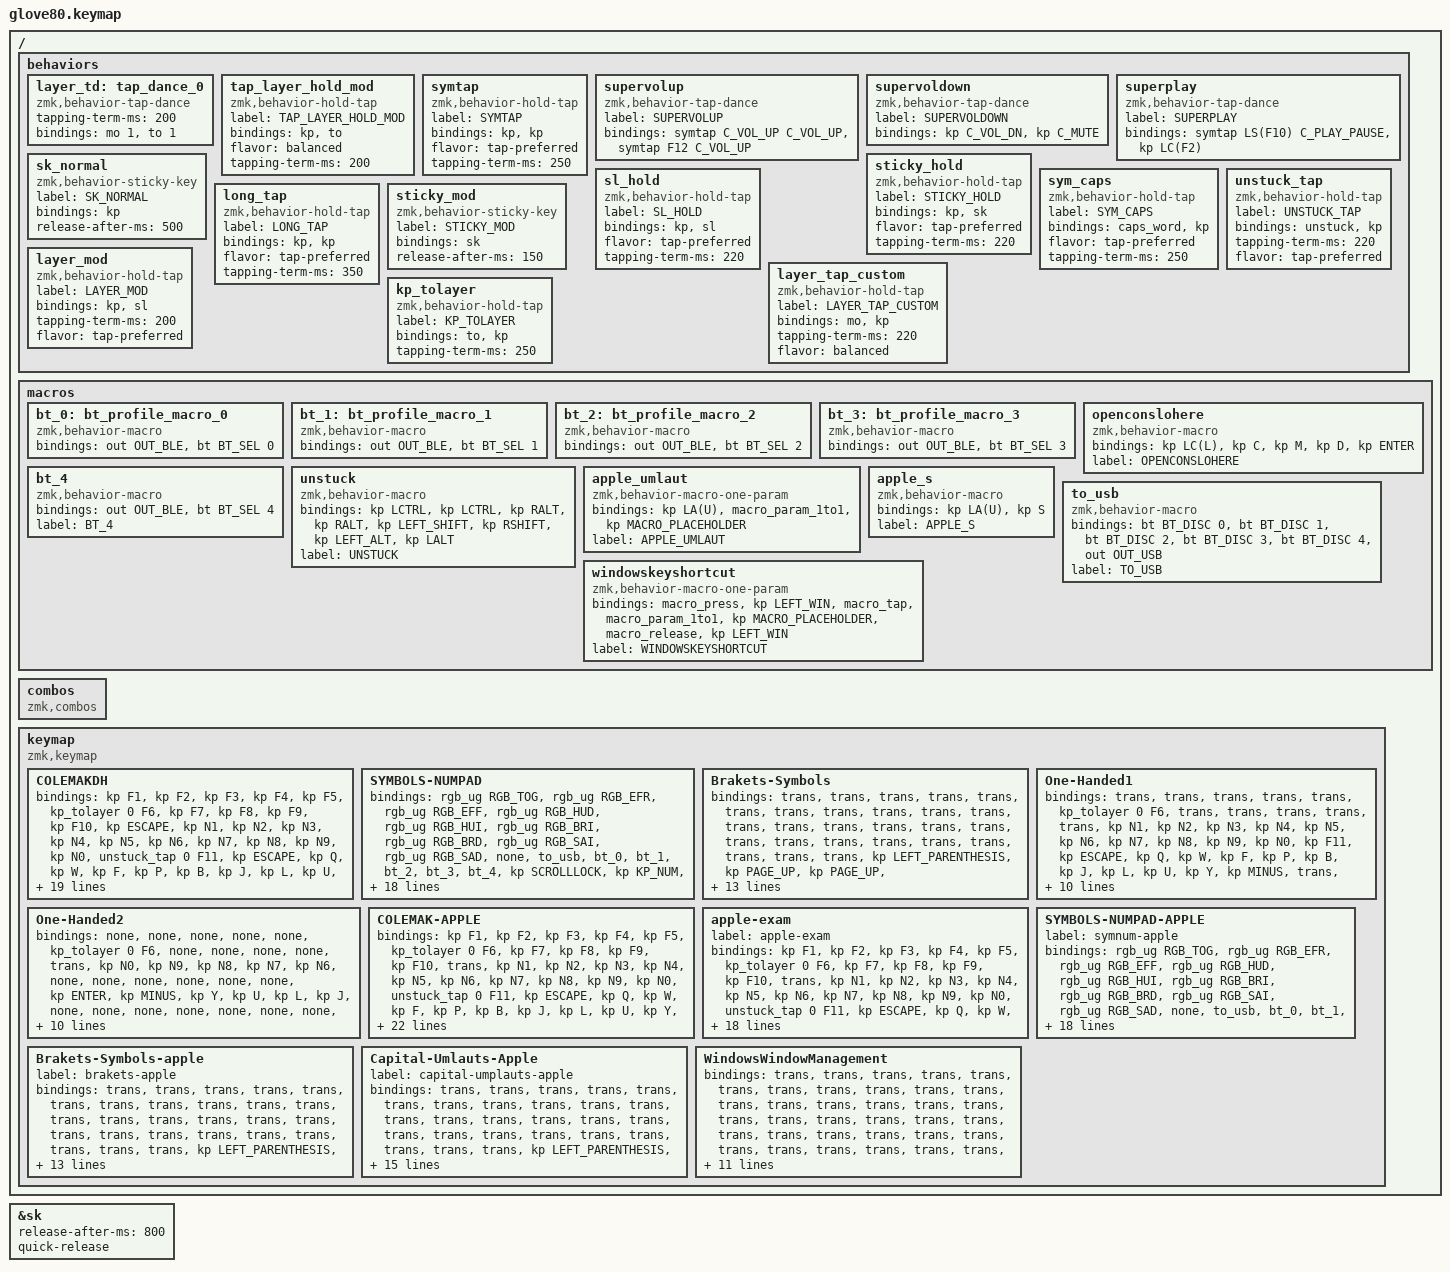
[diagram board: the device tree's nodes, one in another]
/*
 * Copyright (c) 2020 The ZMK Contributors
 *
 * SPDX-License-Identifier: MIT
 */

#include <behaviors.dtsi>
#include <dt-bindings/zmk/backlight.h>
#include <dt-bindings/zmk/bt.h>
#include <dt-bindings/zmk/keys.h>
#include <dt-bindings/zmk/outputs.h>
#include <dt-bindings/zmk/rgb.h>

// layers

#define DEFAULT 0
#define LOWER 1
#define MAGIC 2

&sk {
    release-after-ms = <800>;
    quick-release;
};

/ {
    behaviors {
        // For the "layer" key, it'd nice to be able to use it as either a shift or a toggle.
        // Configure it as a tap dance, so the first tap (or hold) is a &mo and the second tap is a &to

        layer_td: tap_dance_0 {
            compatible = "zmk,behavior-tap-dance";
            #binding-cells = <0>;
            tapping-term-ms = <200>;
            bindings = <&mo 1>, <&to 1>;
        };

        tap_layer_hold_mod: tap_layer_hold_mod {
            compatible = "zmk,behavior-hold-tap";
            label = "TAP_LAYER_HOLD_MOD";
            bindings = <&kp>, <&to>;

            #binding-cells = <2>;
            flavor = "balanced";
            tapping-term-ms = <200>;
        };

        symtap: symtap {
            compatible = "zmk,behavior-hold-tap";
            label = "SYMTAP";
            bindings = <&kp>, <&kp>;

            #binding-cells = <2>;
            flavor = "tap-preferred";
            tapping-term-ms = <250>;
        };

        supervolup: supervolup {
            compatible = "zmk,behavior-tap-dance";
            label = "SUPERVOLUP";
            #binding-cells = <0>;
            bindings = <&symtap C_VOL_UP C_VOL_UP>, <&symtap F12 C_VOL_UP>;
        };

        supervoldown: supervoldown {
            compatible = "zmk,behavior-tap-dance";
            label = "SUPERVOLDOWN";
            #binding-cells = <0>;
            bindings = <&kp C_VOL_DN>, <&kp C_MUTE>;
        };

        superplay: superplay {
            compatible = "zmk,behavior-tap-dance";
            label = "SUPERPLAY";
            #binding-cells = <0>;
            bindings = <&symtap LS(F10) C_PLAY_PAUSE>, <&kp LC(F2)>;
        };

        sk_normal: sk_normal {
            compatible = "zmk,behavior-sticky-key";
            label = "SK_NORMAL";
            bindings = <&kp>;
            #binding-cells = <1>;
            release-after-ms = <500>;
        };

        sticky_hold: sticky_hold {
            compatible = "zmk,behavior-hold-tap";
            label = "STICKY_HOLD";
            bindings = <&kp>, <&sk>;

            #binding-cells = <2>;
            flavor = "tap-preferred";
            tapping-term-ms = <220>;
        };

        sl_hold: sl_hold {
            compatible = "zmk,behavior-hold-tap";
            label = "SL_HOLD";
            bindings = <&kp>, <&sl>;

            #binding-cells = <2>;
            flavor = "tap-preferred";
            tapping-term-ms = <220>;
        };

        sym_caps: sym_caps {
            compatible = "zmk,behavior-hold-tap";
            label = "SYM_CAPS";
            bindings = <&caps_word>, <&kp>;

            #binding-cells = <2>;
            flavor = "tap-preferred";
            tapping-term-ms = <250>;
        };

        unstuck_tap: unstuck_tap {
            compatible = "zmk,behavior-hold-tap";
            label = "UNSTUCK_TAP";
            bindings = <&unstuck>, <&kp>;

            #binding-cells = <2>;
            tapping-term-ms = <220>;
            flavor = "tap-preferred";
        };

        long_tap: long_tap {
            compatible = "zmk,behavior-hold-tap";
            label = "LONG_TAP";
            bindings = <&kp>, <&kp>;

            #binding-cells = <2>;
            flavor = "tap-preferred";
            tapping-term-ms = <350>;
        };

        sticky_mod: sticky_mod {
            compatible = "zmk,behavior-sticky-key";
            label = "STICKY_MOD";
            bindings = <&sk>;
            #binding-cells = <1>;
            release-after-ms = <150>;
        };

        layer_mod: layer_mod {
            compatible = "zmk,behavior-hold-tap";
            label = "LAYER_MOD";
            bindings = <&kp>, <&sl>;

            #binding-cells = <2>;
            tapping-term-ms = <200>;
            flavor = "tap-preferred";
        };

        layer_tap_custom: layer_tap_custom {
            compatible = "zmk,behavior-hold-tap";
            label = "LAYER_TAP_CUSTOM";
            bindings = <&mo>, <&kp>;

            #binding-cells = <2>;
            tapping-term-ms = <220>;
            flavor = "balanced";
        };

        kp_tolayer: kp_tolayer {
            compatible = "zmk,behavior-hold-tap";
            label = "KP_TOLAYER";
            bindings = <&to>, <&kp>;

            #binding-cells = <2>;
            tapping-term-ms = <250>;
        };
    };

    macros {
        bt_0: bt_profile_macro_0 {
            compatible = "zmk,behavior-macro";
            #binding-cells = <0>;
            bindings = <&out OUT_BLE &bt BT_SEL 0>;
        };

        bt_1: bt_profile_macro_1 {
            compatible = "zmk,behavior-macro";
            #binding-cells = <0>;
            bindings = <&out OUT_BLE &bt BT_SEL 1>;
        };

        bt_2: bt_profile_macro_2 {
            compatible = "zmk,behavior-macro";
            #binding-cells = <0>;
            bindings = <&out OUT_BLE &bt BT_SEL 2>;
        };

        bt_3: bt_profile_macro_3 {
            compatible = "zmk,behavior-macro";
            #binding-cells = <0>;
            bindings = <&out OUT_BLE &bt BT_SEL 3>;
        };

        openconslohere: openconslohere {
            compatible = "zmk,behavior-macro";
            #binding-cells = <0>;
            bindings = <&kp LC(L) &kp C &kp M &kp D &kp ENTER>;
            label = "OPENCONSLOHERE";
        };

        bt_4: bt_4 {
            compatible = "zmk,behavior-macro";
            #binding-cells = <0>;
            bindings = <&out OUT_BLE &bt BT_SEL 4>;
            label = "BT_4";
        };

        unstuck: unstuck {
            compatible = "zmk,behavior-macro";
            #binding-cells = <0>;
            bindings = <&kp LCTRL &kp LCTRL &kp RALT &kp RALT &kp LEFT_SHIFT &kp RSHIFT &kp LEFT_ALT &kp LALT>;
            label = "UNSTUCK";
        };

        apple_umlaut: apple_umlaut {
            compatible = "zmk,behavior-macro-one-param";
            #binding-cells = <1>;
            bindings = <&kp LA(U) &macro_param_1to1 &kp MACRO_PLACEHOLDER>;
            label = "APPLE_UMLAUT";
        };

        apple_s: apple_s {
            compatible = "zmk,behavior-macro";
            #binding-cells = <0>;
            bindings = <&kp LA(U) &kp S>;
            label = "APPLE_S";
        };

        to_usb: to_usb {
            compatible = "zmk,behavior-macro";
            #binding-cells = <0>;
            bindings = <&bt BT_DISC 0 &bt BT_DISC 1 &bt BT_DISC 2 &bt BT_DISC 3 &bt BT_DISC 4 &out OUT_USB>;
            label = "TO_USB";
        };

        windowskeyshortcut: windowskeyshortcut {
            compatible = "zmk,behavior-macro-one-param";
            #binding-cells = <1>;
            bindings =
                <&macro_press>,
                <&kp LEFT_WIN>,
                <&macro_tap>,
                <&macro_param_1to1 &kp MACRO_PLACEHOLDER>,
                <&macro_release>,
                <&kp LEFT_WIN>;

            label = "WINDOWSKEYSHORTCUT";
        };
    };

    combos { compatible = "zmk,combos"; };

    keymap {
        compatible = "zmk,keymap";

        COLEMAKDH {
            // ---------------------------------------------------------------------------------------------------------------------------------
            // |  F1   |  F2 |  F3 |  F4  |  F5  |                                                               |  F6   |  F7   |  F8  |   F9  |  F10 |
            // |  =    |  1  |  2  |  3   |  4   |  5   |                                                 |  6   |   7   |   8   |  9   |   0   |   -  |
            // |  TAB  |  Q  |  W  |  E   |  R   |  T   |                                                 |  Y   |   U   |   I   |  O   |   P   |   \  |
            // |  ESC  |  A  |  S  |  D   |  F   |  G   |                                                 |  H   |   J   |   K   |  L   |   ;   |   '  |
            // |   `   |  Z  |  X  |  C   |  V   |  B   | LSHFT | LCTRL | LOWER | | LGUI  | RCTRL | RSHFT |  N   |   M   |   ,   |  .   |   /   | PGUP |
            // | MAGIC | HOME| END | LEFT | RIGHT|      | BSPC  | DEL   | LALT  | | RALT  | RET   | SPACE |      |  UP   | DOWN  |  [   |   ]   | PGDN |

            bindings = <
&kp F1                    &kp F2         &kp F3           &kp F4                 &kp F5                                                                                                                                                                                     &kp_tolayer 0 F6                 &kp F7                 &kp F8             &kp F9      &kp F10
&kp ESCAPE                &kp N1         &kp N2           &kp N3                 &kp N4                   &kp N5                                                                                                                                                    &kp N6  &kp N7                           &kp N8                 &kp N9             &kp N0      &unstuck_tap 0 F11
&kp ESCAPE                &kp Q          &kp W            &kp F                  &kp P                    &kp B                                                                                                                                                     &kp J   &kp L                            &kp U                  &kp Y              &kp MINUS   &symtap F12 ENTER
&kp TAB                   &kp A          &symtap LCTRL R  &layer_tap_custom 2 S  &symtap LS(LA(RCTRL)) T  &kp G                                                                                                                                                     &kp M   &symtap LS(LA(RIGHT_CONTROL)) N  &layer_tap_custom 2 E  &long_tap LCTRL I  &lt 10 O    &symtap LCTRL SQT
&symtap LEFT_SHIFT EQUAL  &kp Z          &kp X            &kp C                  &kp D                    &kp V   &symtap LEFT_ALT ESC  &symtap LS(HOME) HOME    &kp LEFT_GUI                  &none                         &symtap LS(END) END  &symtap RALT ESC  &kp K   &kp H                            &kp COMMA              &kp PERIOD         &kp SLASH   &sym_caps 0 BACKSLASH
&kp LA(LC(F13))           &supervoldown  &supervolup      &kp LEFT               &kp RIGHT                        &lt 1 SPACE           &symtap LCTRL BACKSPACE  &mt LA(LS(RCTRL)) LG(LS(F1))  &symtap LS(LA(RCTRL)) ESCAPE  &symtap LCTRL DEL    &sk LEFT_SHIFT            &kp UP                           &kp DOWN               &kp C_PREVIOUS     &kp C_NEXT  &superplay
            >;

            label = "main";
        };

        SYMBOLS-NUMPAD {
            bindings = <
&rgb_ug RGB_TOG  &rgb_ug RGB_EFR  &rgb_ug RGB_EFF    &rgb_ug RGB_HUD  &rgb_ug RGB_HUI                                                                                         &rgb_ug RGB_BRI  &rgb_ug RGB_BRD  &rgb_ug RGB_SAI  &rgb_ug RGB_SAD  &none
&to_usb          &bt_0            &bt_1              &bt_2            &bt_3            &bt_4                                                                  &kp SCROLLLOCK  &kp KP_NUM       &kp KP_EQUAL     &kp KP_DIVIDE    &kp KP_MULTIPLY  &out OUT_USB
&kp ENTER        &kp SLASH        &kp ASTERISK       &kp AMPERSAND    &kp GRAVE        &kp PAGE_UP                                                            &kp PAGE_UP     &kp KP_N7        &kp KP_N8        &kp KP_N9        &kp KP_MINUS     &trans
&kp INS          &kp HASH         &kp LS(NUMBER_4)   &kp RA(N5)       &kp AT_SIGN      &kp EXCLAMATION                                                        &kp COLON       &kp KP_N4        &kp KP_N5        &kp KP_N6        &kp KP_NUMBER_0  &trans
&kp PLUS         &kp PERCENT      &kp RA(SEMICOLON)  &kp TILDE        &kp CARET        &kp PAGE_DOWN    &trans  &trans  &trans  &to 0  &to 5      &to 3       &kp PAGE_DOWN   &kp KP_N1        &kp KP_NUMBER_2  &kp KP_NUMBER_3  &kp SLASH        &trans
&bl BL_ON        &bl BL_OFF       &bl BL_CYCLE       &kp ENTER        &bt BT_CLR                        &to 0   &trans  &trans  &to 6  &kp COMMA  &kp PERIOD                  &none            &none            &none            &none            &trans
            >;

            label = "symnum";
        };

        Brakets-Symbols {
            bindings = <
&trans    &trans     &trans  &trans     &trans                                                                                                &trans                 &trans         &trans             &trans                &trans
&trans    &trans     &trans  &trans     &trans                &trans                                                           &trans         &trans                 &trans         &trans             &trans                &trans
&trans    &trans     &trans  &trans     &kp LEFT_PARENTHESIS  &kp PAGE_UP                                                      &kp PAGE_UP    &kp RIGHT_PARENTHESIS  &kp RA(U)      &trans             &trans                &trans
&trans    &kp RA(A)  &trans  &kp RA(S)  &kp LEFT_BRACKET      &kp EXCLAMATION                                                  &kp COLON      &kp RIGHT_BRACKET      &kp LEFT       &kp RIGHT          &kp RA(O)             &trans
&kp PLUS  &trans     &trans  &trans     &kp LBRC              &kp PAGE_DOWN    &to 0   &trans  &trans  &trans  &trans  &trans  &kp PAGE_DOWN  &kp RBRC               &kp SEMICOLON  &kp LS(SEMICOLON)  &kp NON_US_BACKSLASH  &kp PIPE
&trans    &trans     &trans  &trans     &trans                                 &trans  &trans  &trans  &trans  &trans  &trans                 &trans                 &trans         &trans             &trans                &trans
            >;

            label = "brakets";
        };

        One-Handed1 {
            bindings = <
&trans          &trans  &trans  &trans  &trans                                                                                        &kp_tolayer 0 F6  &trans     &trans   &trans     &trans
&trans          &kp N1  &kp N2  &kp N3  &kp N4  &kp N5                                                                        &kp N6  &kp N7            &kp N8     &kp N9   &kp N0     &kp F11
&kp ESCAPE      &kp Q   &kp W   &kp F   &kp P   &kp B                                                                         &kp J   &kp L             &kp U      &kp Y    &kp MINUS  &trans
&kp TAB         &kp A   &kp R   &kp S   &kp T   &kp G                                                                         &kp M   &kp N             &kp E      &kp I    &kp O      &trans
&kp LEFT_SHIFT  &kp Z   &kp X   &kp C   &kp D   &kp V   &kp LEFT_ALT  &kp LCTRL      &trans  &none   &trans   &trans          &kp K   &kp H             &kp COMMA  &kp DOT  &kp FSLH   &trans
&trans          &trans  &trans  &trans  &trans          &kp SPACE     &kp BACKSPACE  &mo 4   &trans  &kp DEL  &kp LEFT_SHIFT          &trans            &trans     &trans   &trans     &trans
            >;

            label = "games";
        };

        One-Handed2 {
            bindings = <
&none       &none           &none       &none      &none                                                                                       &kp_tolayer 0 F6  &none  &none  &none  &none
&trans      &kp N0          &kp N9      &kp N8     &kp N7  &kp N6                                                                       &none  &none             &none  &none  &none  &none
&kp ENTER   &kp MINUS       &kp Y       &kp U      &kp L   &kp J                                                                        &none  &none             &none  &none  &none  &none
&none       &kp O           &kp I       &kp E      &kp N   &kp M                                                                        &none  &none             &none  &none  &none  &none
&none       &kp FSLH        &kp DOT     &kp COMMA  &kp H   &kp K   &symtap LCTRL DEL  &symtap LS(END) END  &trans  &none  &none  &none  &none  &none             &none  &none  &none  &none
&superplay  &kp C_PREVIOUS  &kp C_NEXT  &kp DOWN   &kp UP          &sk LEFT_SHIFT     &symtap LS(END) END  &trans  &none  &none  &none         &none             &none  &none  &none  &none
            >;

            label = "mirror-right";
        };

        COLEMAK-APPLE {
            bindings = <
&kp F1                &kp F2                    &kp F3             &kp F4                 &kp F5                                                                                                                                                                                                     &kp_tolayer 0 F6                 &kp F7                 &kp F8             &kp F9                    &kp F10
&trans                &kp N1                    &kp N2             &kp N3                 &kp N4                           &kp N5                                                                                                                                                            &kp N6  &kp N7                           &kp N8                 &kp N9             &kp N0                    &unstuck_tap 0 F11
&kp ESCAPE            &kp Q                     &kp W              &kp F                  &kp P                            &kp B                                                                                                                                                             &kp J   &kp L                            &kp U                  &kp Y              &kp MINUS                 &symtap F12 ENTER
&mt LA(LGUI) TAB      &long_tap LEFT_COMMAND A  &long_tap LCTRL R  &layer_tap_custom 8 S  &symtap LS(LA(RIGHT_CONTROL)) T  &kp G                                                                                                                                                             &kp M   &symtap LS(LA(RIGHT_CONTROL)) N  &layer_tap_custom 8 E  &long_tap LCTRL I  &long_tap LA(LEFT_GUI) O  &symtap LEFT_COMMAND SQT
&mt LEFT_SHIFT EQUAL  &kp Z                     &kp X              &kp C                  &kp D                            &kp V   &kp LEFT_ALT  &symtap LG(LS(LEFT)) LG(LEFT)  &kp LCTRL                     &none                         &symtap LS(LG(RIGHT)) LG(RIGHT)  &kp RALT        &kp K   &kp H                            &kp COMMA              &kp PERIOD         &kp SLASH                 &sym_caps 0 BACKSLASH
&kp LA(LC(F13))       &supervoldown             &supervolup        &kp LEFT               &kp RIGHT                                &lt 7 SPACE   &symtap LEFT_GUI BACKSPACE     &mt LA(LS(RCTRL)) LG(LS(F1))  &symtap LS(LA(RCTRL)) ESCAPE  &symtap LALT DEL                 &sk LEFT_SHIFT          &kp UP                           &kp DOWN               &kp C_PREVIOUS     &kp C_NEXT                &superplay
            >;

            label = "apple";
        };

        apple-exam {
            label = "apple-exam";
            bindings = <
&kp F1                &kp F2                    &kp F3             &kp F4                 &kp F5                                                                                                                                          &kp_tolayer 0 F6  &kp F7                 &kp F8             &kp F9      &kp F10
&trans                &kp N1                    &kp N2             &kp N3                 &kp N4     &kp N5                                                                                                                       &kp N6  &kp N7            &kp N8                 &kp N9             &kp N0      &unstuck_tap 0 F11
&kp ESCAPE            &kp Q                     &kp W              &kp F                  &kp P      &kp B                                                                                                                        &kp J   &kp L             &kp U                  &kp Y              &kp MINUS   &symtap F12 ENTER
&kp TAB               &long_tap LEFT_COMMAND A  &long_tap LCTRL R  &layer_tap_custom 8 S  &kp T      &kp G                                                                                                                        &kp M   &kp N             &layer_tap_custom 8 E  &long_tap LCTRL I  &kp O       &symtap LEFT_COMMAND SQT
&mt LEFT_SHIFT EQUAL  &kp Z                     &kp X              &kp C                  &kp D      &kp V   &kp LEFT_ALT  &symtap LG(LS(LEFT)) LG(LEFT)  &kp LCTRL  &none       &symtap LS(LG(RIGHT)) LG(RIGHT)  &kp RALT        &kp K   &kp H             &kp COMMA              &kp PERIOD         &kp SLASH   &sym_caps 0 BACKSLASH
&none                 &supervoldown             &supervolup        &kp LEFT               &kp RIGHT          &lt 7 SPACE   &symtap LEFT_GUI BACKSPACE     &none      &kp ESCAPE  &symtap LALT DEL                 &sk LEFT_SHIFT          &kp UP            &kp DOWN               &kp C_PREVIOUS     &kp C_NEXT  &superplay
            >;
        };

        SYMBOLS-NUMPAD-APPLE {
            label = "symnum-apple";
            bindings = <
&rgb_ug RGB_TOG  &rgb_ug RGB_EFR  &rgb_ug RGB_EFF   &rgb_ug RGB_HUD       &rgb_ug RGB_HUI                                                                                          &rgb_ug RGB_BRI  &rgb_ug RGB_BRD  &rgb_ug RGB_SAI  &rgb_ug RGB_SAD  &none
&to_usb          &bt_0            &bt_1             &bt_2                 &bt_3            &bt_4                                                                   &kp SCROLLLOCK  &kp KP_NUM       &kp KP_EQUAL     &kp KP_DIVIDE    &kp KP_MULTIPLY  &out OUT_USB
&kp ENTER        &kp SLASH        &kp ASTERISK      &kp AMPERSAND         &kp GRAVE        &kp PAGE_UP                                                             &kp PAGE_UP     &kp KP_N7        &kp KP_N8        &kp KP_N9        &kp KP_MINUS     &trans
&kp INS          &kp HASH         &kp LS(NUMBER_4)  &kp LA(LS(NUMBER_2))  &kp AT_SIGN      &kp EXCLAMATION                                                         &kp COLON       &kp KP_N4        &kp KP_N5        &kp KP_N6        &kp KP_NUMBER_0  &trans
&kp PLUS         &kp PERCENT      &kp RA(NUMBER_0)  &kp TILDE             &kp CARET        &kp PAGE_DOWN    &trans  &trans  &trans  &trans  &trans     &none       &kp PAGE_DOWN   &kp KP_N1        &kp KP_NUMBER_2  &kp KP_NUMBER_3  &kp SLASH        &trans
&bl BL_ON        &bl BL_OFF       &bl BL_CYCLE      &kp ENTER             &bt BT_CLR                        &to 5   &trans  &trans  &trans  &kp COMMA  &kp PERIOD                  &none            &none            &none            &none            &trans
            >;
        };

        Brakets-Symbols-apple {
            label = "brakets-apple";
            bindings = <
&trans    &trans           &trans  &trans     &trans                                                                                                &trans                 &trans           &trans             &trans                &trans
&trans    &trans           &trans  &trans     &trans                &trans                                                           &trans         &trans                 &trans           &trans             &trans                &trans
&trans    &trans           &trans  &trans     &kp LEFT_PARENTHESIS  &kp PAGE_UP                                                      &kp PAGE_UP    &kp RIGHT_PARENTHESIS  &apple_umlaut U  &trans             &trans                &trans
&trans    &apple_umlaut A  &trans  &kp LA(S)  &kp LEFT_BRACKET      &kp EXCLAMATION                                                  &kp COLON      &kp RIGHT_BRACKET      &trans           &trans             &apple_umlaut O       &kp DOUBLE_QUOTES
&kp PLUS  &trans           &trans  &trans     &kp LBRC              &kp PAGE_DOWN    &to 0   &trans  &trans  &trans  &trans  &trans  &kp PAGE_DOWN  &kp RBRC               &kp SEMICOLON    &kp LS(SEMICOLON)  &kp NON_US_BACKSLASH  &kp PIPE
&trans    &trans           &trans  &trans     &trans                                 &trans  &trans  &trans  &trans  &trans  &mo 9                  &trans                 &trans           &trans             &trans                &trans
            >;
        };

        Capital-Umlauts-Apple {
            label = "capital-umplauts-apple";
            bindings = <
&trans    &trans               &trans  &trans     &trans                                                                                                &trans                 &trans               &trans             &trans                &trans
&trans    &trans               &trans  &trans     &trans                &trans                                                           &trans         &trans                 &trans               &trans             &trans                &trans
&trans    &trans               &trans  &trans     &kp LEFT_PARENTHESIS  &kp PAGE_UP                                                      &kp PAGE_UP    &kp RIGHT_PARENTHESIS  &apple_umlaut LS(U)  &trans             &trans                &trans
&trans    &apple_umlaut LS(A)  &trans  &kp LA(S)  &kp LEFT_BRACKET      &kp EXCLAMATION                                                  &kp COLON      &kp RIGHT_BRACKET      &trans               &trans             &apple_umlaut LS(O)   &kp DOUBLE_QUOTES
&kp PLUS  &trans               &trans  &trans     &kp LBRC              &kp PAGE_DOWN    &to 0   &trans  &trans  &trans  &trans  &trans  &kp PAGE_DOWN  &kp RBRC               &kp SEMICOLON        &kp LS(SEMICOLON)  &kp NON_US_BACKSLASH  &kp PIPE
&trans    &trans               &trans  &trans     &trans                                 &trans  &trans  &trans  &trans  &trans  &trans                 &trans                 &trans               &trans             &trans                &trans
            >;
        };

        WindowsWindowManagement {
            bindings = <
&trans  &trans                    &trans                     &trans                    &trans                                                                                  &trans  &trans  &trans  &trans  &trans
&trans  &trans                    &trans                     &trans                    &trans                  &trans                                                  &trans  &trans  &trans  &trans  &trans  &trans
&trans  &trans                    &trans                     &trans                    &trans                  &trans                                                  &trans  &trans  &trans  &trans  &trans  &trans
&trans  &windowskeyshortcut LEFT  &windowskeyshortcut RIGHT  &windowskeyshortcut DOWN  &windowskeyshortcut UP  &trans                                                  &trans  &trans  &trans  &trans  &trans  &trans
&trans  &trans                    &trans                     &trans                    &trans                  &trans  &trans  &trans  &trans  &trans  &trans  &trans  &trans  &trans  &trans  &trans  &trans  &trans
&trans  &trans                    &trans                     &trans                    &trans                          &trans  &trans  &trans  &trans  &trans  &trans          &trans  &trans  &trans  &trans  &trans
            >;
        };
    };
};
